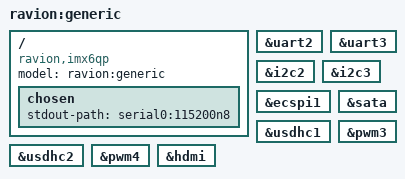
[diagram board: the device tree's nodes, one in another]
/*
 * Copyright 2018 Radioavionica Corp.
 *
 * Author: Alex A. Mihaylov <minimumlaw@rambler.ru>
 *
 * This program is free software; you can redistribute it and/or modify
 * it under the terms of the GNU General Public License version 2 as
 * published by the Free Software Foundation.
 *
 */
/dts-v1/;

#include <dt-bindings/clock/imx6qdl-clock.h>
#include "imx6qp.dtsi"
#include "imx6qdl-ravion-v2.dtsi"
#include "imx6qp-ravion-u-boot.dtsi"

/ {
	model = "ravion:generic";
	compatible = "ravion,imx6qp", "fsl,imx6qp";

	chosen {
		stdout-path = "serial0:115200n8";
	};

};


/*
 * Serial ports
 */
/* &uart1 {	status = "okay";	}; => Allways enabled */
&uart2 {	status = "okay";	};
&uart3 {	status = "okay";	};

/*
 * I2C Busses
 */
/* &i2c1 {	status = "okay";	}; => Allways enabled */

&i2c2 {	/* Compatible I2C: soDimm 194, 196 */
	status = "okay";
};

&i2c3 { /* Extended I2C: soDimm 128, 130 */
	status = "okay";
};

/*
 * SPI Bus
 */
&ecspi1 {	status = "okay";	};


/*
 * SD/MMC and eMMC controllers
 */
&usdhc1 {	status = "okay";	}; /* compatible */
&usdhc2 {	status = "okay";	}; /* externed */
/* &usdhc3 {	status = "okay";	}; => eMMC allways enabled */

/*
 * Ethernet controller
 */
/* &fec {	status = "okay";	}; => eth0 allways enabled */

/*
 * Audio (digital part)
 */
/* &audmux {	status = "okay";	}; => Allways enabled */
/* &ssi1 {	status = "okay";	}; => Allways enabled */

/*
 * High-speed serial bus
 */
/* &pcie {	status = "okay";	}; => disabled, not ethernet, not storage */
&sata	{	status = "okay";	};
/* &usbh1  {	status = "okay";	}; => Allways enabled */
/* &usbotg`{	status = "okay";	}; => Allways enabled */
/* &usbh3  {	status = "okay";	}; => HSIC interface disabled - no hub */

/*
 * PWMs
 */
&pwm3	{	status = "okay";	};
&pwm4	{	status = "okay";	};

/*
 * Video subsystems
 */
&hdmi	{	status = "okay";	};
